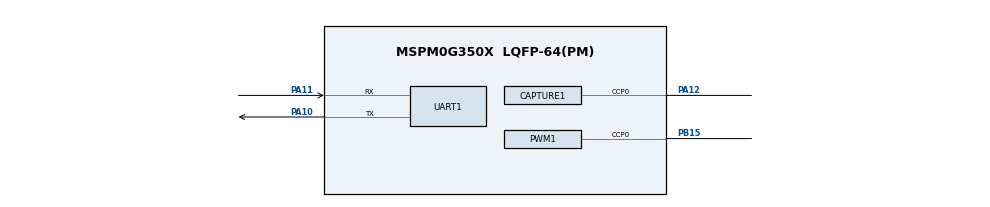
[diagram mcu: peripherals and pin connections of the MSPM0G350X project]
/**
 * @cliArgs --device "MSPM0G350X" --part "Default" --package "LQFP-64(PM)" --product "mspm0_sdk@2.05.01.00"
 * @versions {"tool":"1.25.0+4268"}
 */

/**
 * Import the modules used in this configuration.
 */
const CAPTURE  = scripting.addModule("/ti/driverlib/CAPTURE", {}, false);
const CAPTURE1 = CAPTURE.addInstance();
const PWM      = scripting.addModule("/ti/driverlib/PWM", {}, false);
const PWM1     = PWM.addInstance();
const SYSCTL   = scripting.addModule("/ti/driverlib/SYSCTL");
const UART     = scripting.addModule("/ti/driverlib/UART", {}, false);
const UART1    = UART.addInstance();

/**
 * Write custom configuration values to the imported modules.
 */
CAPTURE1.$name                      = "CAPTURE_0";
CAPTURE1.timerClkPrescale           = 256;
CAPTURE1.timerPeriod                = "524.29ms";
CAPTURE1.interrupts                 = ["CC0_DN","ZERO"];
CAPTURE1.peripheral.$assign         = "TIMG0";
CAPTURE1.peripheral.ccp0Pin.$assign = "PA12";
CAPTURE1.ccp0PinConfig.$name        = "ti_driverlib_gpio_GPIOPinGeneric3";

const Board = scripting.addModule("/ti/driverlib/Board", {}, false);

PWM1.$name                      = "PWM_0";
PWM1.clockPrescale              = 256;
PWM1.ccIndex                    = [0];
PWM1.PWM_CHANNEL_0.$name        = "ti_driverlib_pwm_PWMTimerCC0";
PWM1.PWM_CHANNEL_0.dutyCycle    = 50;
PWM1.ccp0PinConfig.$name        = "ti_driverlib_gpio_GPIOPinGeneric2";
PWM1.peripheral.$assign         = "TIMG7";
PWM1.peripheral.ccp0Pin.$assign = "PB15";

SYSCTL.forceDefaultClkConfig = true;

UART1.$name                    = "UART_0";
UART1.enabledInterrupts        = ["RX"];
UART1.targetBaudRate           = 2000000;
UART1.peripheral.rxPin.$assign = "PA11";
UART1.peripheral.txPin.$assign = "PA10";
UART1.txPinConfig.$name        = "ti_driverlib_gpio_GPIOPinGeneric0";
UART1.rxPinConfig.$name        = "ti_driverlib_gpio_GPIOPinGeneric1";

/**
 * Pinmux solution for unlocked pins/peripherals. This ensures that minor changes to the automatic solver in a future
 * version of the tool will not impact the pinmux you originally saw.  These lines can be completely deleted in order to
 * re-solve from scratch.
 */
Board.peripheral.$suggestSolution          = "DEBUGSS";
Board.peripheral.swclkPin.$suggestSolution = "PA20";
Board.peripheral.swdioPin.$suggestSolution = "PA19";
SYSCTL.peripheral.$suggestSolution         = "SYSCTL";
UART1.peripheral.$suggestSolution          = "UART0";
